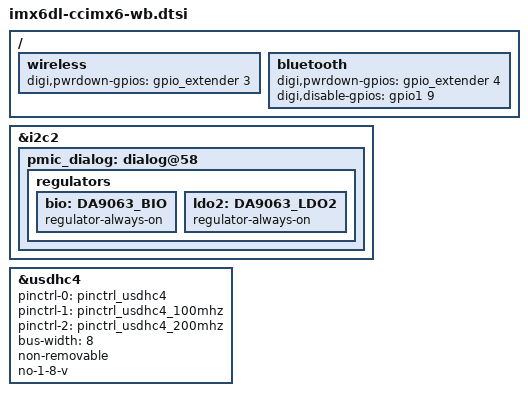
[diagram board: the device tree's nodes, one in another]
/*
 * Copyright 2015 Digi International, Inc.
 *
 * The code contained herein is licensed under the GNU General Public
 * License. You may obtain a copy of the GNU General Public License
 * Version 2 or later at the following locations:
 *
 * http://www.opensource.org/licenses/gpl-license.html
 * http://www.gnu.org/copyleft/gpl.html
 */

#include "imx6dl.dtsi"
/* ConnectCore 6 (common)*/
#include "imx6qdl-ccimx6.dtsi"

/ {
	wireless {
		digi,pwrdown-gpios = <&gpio_extender 3 0>;
		/* U-Boot will fill in the MAC address here */
	};

	bluetooth {
		digi,pwrdown-gpios = <&gpio_extender 4 0>;
		digi,disable-gpios = <&gpio1 9 0>;
		/* U-Boot will fill in the MAC address here */
	};
};

&i2c2 {
	pmic_dialog: dialog@58 {
		regulators {
			bio: DA9063_BIO {
				regulator-always-on;
			};

			ldo2: DA9063_LDO2 {
				regulator-always-on;
			};
		};
	};
};

&usdhc4 {
	pinctrl-names = "default", "state_100mhz", "state_200mhz";
	pinctrl-0 = <&pinctrl_usdhc4>;
	pinctrl-1 = <&pinctrl_usdhc4_100mhz>;
	pinctrl-2 = <&pinctrl_usdhc4_200mhz>;
	bus-width = <8>;
	non-removable;
	no-1-8-v;
	status = "okay";
};
